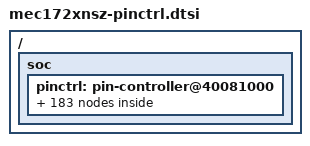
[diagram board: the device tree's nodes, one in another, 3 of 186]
/*
 * Copyright (c) 2021 Microchip Technology Inc.
 *
 * SPDX-License-Identifier: Apache-2.0
 */

#include <dt-bindings/pinctrl/mchp-xec-pinctrl.h>

/ {
	soc {
		pinctrl: pin-controller@40081000 {

			/* ADC */
			pinctrl_adc0_in0: adc0_in0 {
				pinmux = < MCHP_XEC_PINMUX(0200, AF1) >;
			};

			pinctrl_adc0_in1: adc0_in1 {
				pinmux = < MCHP_XEC_PINMUX(0201, AF1) >;
			};

			pinctrl_adc0_in2: adc0_in2 {
				pinmux = < MCHP_XEC_PINMUX(0202, AF1) >;
			};

			pinctrl_adc0_in3: adc0_in3 {
				pinmux = < MCHP_XEC_PINMUX(0203, AF1) >;
			};

			pinctrl_adc0_in4: adc0_in4 {
				pinmux = < MCHP_XEC_PINMUX(0204, AF1) >;
			};

			pinctrl_adc0_in5: adc0_in5 {
				pinmux = < MCHP_XEC_PINMUX(0205, AF1) >;
			};

			pinctrl_adc0_in6: adc0_in6 {
				pinmux = < MCHP_XEC_PINMUX(0206, AF1) >;
			};

			pinctrl_adc0_in7: adc0_in7 {
				pinmux = < MCHP_XEC_PINMUX(0207, AF1) >;
			};

			pinctrl_adc0_vref2: adc0_vref2 {
				pinmux = < MCHP_XEC_PINMUX(067, AF1) >;
			};

			/* BBLED */
			pinctrl_bbled0: bbled0 {
				pinmux = < MCHP_XEC_PINMUX(0156, AF1) >;
			};

			pinctrl_bbled1: bbled1 {
				pinmux = < MCHP_XEC_PINMUX(0157, AF1) >;
			};

			pinctrl_bbled1: bbled1 {
				pinmux = < MCHP_XEC_PINMUX(0153, AF1) >;
			};

			/* eSPI */
			pinctrl_espi_alert: espi_alert {
				pinmux = < MCHP_XEC_PINMUX(063, AF1) >;
				bias-pull-up;
				drive-open-drain;
			};

			pinctrl_espi_clk: espi_clk {
				pinmux = < MCHP_XEC_PINMUX(065, AF1) >;
				slew-rate = "high-speed";
			};

			pinctrl_espi_cs: espi_cs {
				pinmux = < MCHP_XEC_PINMUX(066, AF1) >;
				bias-pull-up;
				drive-open-drain;
			};

			pinctrl_espi_io0: espi_io0 {
				pinmux = < MCHP_XEC_PINMUX(070, AF1) >;
				slew-rate = "high-speed";
			};

			pinctrl_espi_io1: espi_io1 {
				pinmux = < MCHP_XEC_PINMUX(071, AF1) >;
				slew-rate = "high-speed";
			};

			pinctrl_espi_io2: espi_io2 {
				pinmux = < MCHP_XEC_PINMUX(072, AF1) >;
				slew-rate = "high-speed";
			};

			pinctrl_espi_io3: espi_io3 {
				pinmux = < MCHP_XEC_PINMUX(073, AF1) >;
				slew-rate = "high-speed";
			};

			pinctrl_espi_reset: espi_reset {
				pinmux = < MCHP_XEC_PINMUX(061, AF1) >;
				bias-pull-up;
				drive-open-drain;
			};

			/* GPIO Pass Through */
			pinctrl_gptp_in0: gptp_in0 {
				pinmux = < MCHP_XEC_PINMUX(0224, AF1) >;
			};

			pinctrl_gptp_out0: gptp_out0 {
				pinmux = < MCHP_XEC_PINMUX(032, AF2) >;
			};

			pinctrl_gptp_in1: gptp_in1 {
				pinmux = < MCHP_XEC_PINMUX(016, AF1) >;
			};

			pinctrl_gptp_out1: gptp_out1 {
				pinmux = < MCHP_XEC_PINMUX(031, AF2) >;
			};

			pinctrl_gptp_in2: gptp_in2 {
				pinmux = < MCHP_XEC_PINMUX(014, AF3) >;
			};

			pinctrl_gptp_out2: gptp_out2 {
				pinmux = < MCHP_XEC_PINMUX(040, AF1) >;
			};

			pinctrl_gptp_in3: gptp_in3 {
				pinmux = < MCHP_XEC_PINMUX(0221, AF2) >;
			};

			pinctrl_gptp_out3: gptp_out3 {
				pinmux = < MCHP_XEC_PINMUX(0152, AF3) >;
			};

			pinctrl_gptp_in5: gptp_in5 {
				pinmux = < MCHP_XEC_PINMUX(017, AF3) >;
			};

			pinctrl_gptp_out5: gptp_out5 {
				pinmux = < MCHP_XEC_PINMUX(0125, AF3) >;
			};

			pinctrl_gptp_in6: gptp_in6 {
				pinmux = < MCHP_XEC_PINMUX(024, AF2) >;
			};

			pinctrl_gptp_out6: gptp_out6 {
				pinmux = < MCHP_XEC_PINMUX(0124, AF4) >;
			};

			/* I2C port 0 */
			pinctrl_i2c_scl0: i2c_scl0 {
				pinmux = < MCHP_XEC_PINMUX(004, AF1) >;
				drive-open-drain;
				output-high;
			};

			pinctrl_i2c_sda0: i2c_sda0 {
				pinmux = < MCHP_XEC_PINMUX(003, AF1) >;
				drive-open-drain;
				output-high;
			};

			/* I2C port 1 */
			pinctrl_i2c_scl1: i2c_scl1 {
				pinmux = < MCHP_XEC_PINMUX(0131, AF1) >;
				drive-open-drain;
				output-high;
			};

			pinctrl_i2c_scl1_alt: i2c_scl1_alt {
				pinmux = < MCHP_XEC_PINMUX(073, AF2) >;
				drive-open-drain;
				output-high;
			};

			pinctrl_i2c_sda1: i2c_sda1 {
				pinmux = < MCHP_XEC_PINMUX(0130, AF1) >;
				drive-open-drain;
				output-high;
			};

			pinctrl_i2c_sda1_alt: i2c_sda1_alt {
				pinmux = < MCHP_XEC_PINMUX(072, AF2) >;
				drive-open-drain;
				output-high;
			};

			/* I2C port 2 */
			pinctrl_i2c_scl2: i2c_scl2 {
				pinmux = < MCHP_XEC_PINMUX(0155, AF1) >;
				drive-open-drain;
				output-high;
			};

			pinctrl_i2c_sda2: i2c_sda2 {
				pinmux = < MCHP_XEC_PINMUX(0154, AF1) >;
				drive-open-drain;
				output-high;
			};

			/* I2C port 3 */
			pinctrl_i2c_scl3: i2c_scl3 {
				pinmux = < MCHP_XEC_PINMUX(010, AF1) >;
				drive-open-drain;
				output-high;
			};

			pinctrl_i2c_sda3: i2c_sda3 {
				pinmux = < MCHP_XEC_PINMUX(007, AF1) >;
				drive-open-drain;
				output-high;
			};

			/* I2C port 4 */
			pinctrl_i2c_scl4: i2c_scl4 {
				pinmux = < MCHP_XEC_PINMUX(0144, AF1) >;
				drive-open-drain;
				output-high;
			};

			pinctrl_i2c_sda4: i2c_sda4 {
				pinmux = < MCHP_XEC_PINMUX(0143, AF1) >;
				drive-open-drain;
				output-high;
			};

			/* I2C port 5 */
			pinctrl_i2c_scl5: i2c_scl5 {
				pinmux = < MCHP_XEC_PINMUX(0142, AF1) >;
				drive-open-drain;
				output-high;
			};

			pinctrl_i2c_sda5: i2c_sda5 {
				pinmux = < MCHP_XEC_PINMUX(0141, AF1) >;
				drive-open-drain;
				output-high;
			};

			/* I2C port 6 */
			pinctrl_i2c_scl6: i2c_scl6 {
				pinmux = < MCHP_XEC_PINMUX(0140, AF1) >;
				drive-open-drain;
				output-high;
			};

			pinctrl_i2c_sda6: i2c_sda6 {
				pinmux = < MCHP_XEC_PINMUX(0132, AF1) >;
				drive-open-drain;
				output-high;
			};

			/* I2C port 7 */
			pinctrl_i2c_scl7: i2c_scl7 {
				pinmux = < MCHP_XEC_PINMUX(013, AF1) >;
				drive-open-drain;
				output-high;
			};

			pinctrl_i2c_scl7_alt: i2c_scl7_alt {
				pinmux = < MCHP_XEC_PINMUX(024, AF3) >;
				drive-open-drain;
				output-high;
			};

			pinctrl_i2c_sda7: i2c_sda7 {
				pinmux = < MCHP_XEC_PINMUX(012, AF1) >;
				drive-open-drain;
				output-high;
			};

			pinctrl_i2c_sda7_alt: i2c_sda7_alt {
				pinmux = < MCHP_XEC_PINMUX(0152, AF3) >;
				drive-open-drain;
				output-high;
			};

			/* I2C port 9 */
			pinctrl_i2c_scl9: i2c_scl9 {
				pinmux = < MCHP_XEC_PINMUX(0146, AF1) >;
				drive-open-drain;
				output-high;
			};

			pinctrl_i2c_sda9: i2c_sda9 {
				pinmux = < MCHP_XEC_PINMUX(0145, AF1) >;
				drive-open-drain;
				output-high;
			};

			/* I2C port 10 */
			pinctrl_i2c_scl10: i2c_scl10 {
				pinmux = < MCHP_XEC_PINMUX(0107, AF3) >;
				drive-open-drain;
				output-high;
			};

			pinctrl_i2c_sda10: i2c_sda10 {
				pinmux = < MCHP_XEC_PINMUX(030, AF2) >;
				drive-open-drain;
				output-high;
			};

			/* I2C port 11 */
			pinctrl_i2c_scl11: i2c_scl11 {
				pinmux = < MCHP_XEC_PINMUX(062, AF2) >;
				drive-open-drain;
				output-high;
			};

			pinctrl_i2c_sda11: i2c_sda11 {
				pinmux = < MCHP_XEC_PINMUX(000, AF3) >;
				drive-open-drain;
				output-high;
			};

			/* I2C port 12 */
			pinctrl_i2c_scl12: i2c_scl12 {
				pinmux = < MCHP_XEC_PINMUX(027, AF3) >;
				drive-open-drain;
				output-high;
			};

			pinctrl_i2c_sda12: i2c_sda12 {
				pinmux = < MCHP_XEC_PINMUX(026, AF3) >;
				drive-open-drain;
				output-high;
			};

			/* I2C port 13 */
			pinctrl_i2c_scl13: i2c_scl13 {
				pinmux = < MCHP_XEC_PINMUX(065, AF2) >;
				drive-open-drain;
				output-high;
			};

			pinctrl_i2c_sda13: i2c_sda13 {
				pinmux = < MCHP_XEC_PINMUX(066, AF2) >;
				drive-open-drain;
				output-high;
			};

			/* I2C port 14 */
			pinctrl_i2c_scl14: i2c_scl14 {
				pinmux = < MCHP_XEC_PINMUX(071, AF2) >;
				drive-open-drain;
				output-high;
			};

			pinctrl_i2c_sda14: i2c_sda14 {
				pinmux = < MCHP_XEC_PINMUX(070, AF2) >;
				drive-open-drain;
				output-high;
			};

			/* I2C port 15 */
			pinctrl_i2c_scl15: i2c_scl15 {
				pinmux = < MCHP_XEC_PINMUX(0150, AF1) >;
				drive-open-drain;
				output-high;
			};

			pinctrl_sda15: i2c_sda15 {
				pinmux = < MCHP_XEC_PINMUX(0147, AF1) >;
				drive-open-drain;
				output-high;
			};

			/* KEYSCAN */
			pinctrl_ksi0: ksi0 {
				pinmux = < MCHP_XEC_PINMUX(017, AF1) >;
				bias-pull-up;
				drive-open-drain;
			};

			pinctrl_ksi1: ksi1 {
				pinmux = < MCHP_XEC_PINMUX(020, AF1) >;
				bias-pull-up;
				drive-open-drain;
			};

			pinctrl_ksi2: ksi2 {
				pinmux = < MCHP_XEC_PINMUX(021, AF1) >;
				bias-pull-up;
				drive-open-drain;
			};

			pinctrl_ksi3: ksi3 {
				pinmux = < MCHP_XEC_PINMUX(026, AF1) >;
				bias-pull-up;
				drive-open-drain;
			};

			pinctrl_ksi4: ksi4 {
				pinmux = < MCHP_XEC_PINMUX(027, AF1) >;
				bias-pull-up;
				drive-open-drain;
			};

			pinctrl_ksi5: ksi5 {
				pinmux = < MCHP_XEC_PINMUX(030, AF1) >;
				bias-pull-up;
				drive-open-drain;
			};

			pinctrl_ksi6: ksi6 {
				pinmux = < MCHP_XEC_PINMUX(031, AF1) >;
				bias-pull-up;
				drive-open-drain;
			};

			pinctrl_ksi7: ksi7 {
				pinmux = < MCHP_XEC_PINMUX(032, AF1) >;
				bias-pull-up;
				drive-open-drain;
			};

			pinctrl_kso0: kso0 {
				pinmux = < MCHP_XEC_PINMUX(040, AF2) >;
				bias-pull-up;
				drive-open-drain;
			};

			pinctrl_kso1: kso1 {
				pinmux = < MCHP_XEC_PINMUX(045, AF1) >;
				bias-pull-up;
				drive-open-drain;
			};

			pinctrl_kso2: kso2 {
				pinmux = < MCHP_XEC_PINMUX(046, AF1) >;
				bias-pull-up;
				drive-open-drain;
			};

			pinctrl_kso3: kso3 {
				pinmux = < MCHP_XEC_PINMUX(047, AF1) >;
				bias-pull-up;
				drive-open-drain;
			};

			pinctrl_kso4: kso4 {
				pinmux = < MCHP_XEC_PINMUX(0107, AF2) >;
				bias-pull-up;
				drive-open-drain;
			};

			pinctrl_kso5: kso5 {
				pinmux = < MCHP_XEC_PINMUX(0112, AF1) >;
				bias-pull-up;
				drive-open-drain;
			};

			pinctrl_kso6: kso6 {
				pinmux = < MCHP_XEC_PINMUX(0113, AF1) >;
				bias-pull-up;
				drive-open-drain;
			};

			pinctrl_kso7: kso7 {
				pinmux = < MCHP_XEC_PINMUX(0120, AF1) >;
				bias-pull-up;
				drive-open-drain;
			};

			pinctrl_kso8: kso8 {
				pinmux = < MCHP_XEC_PINMUX(0121, AF2) >;
				bias-pull-up;
				drive-open-drain;
			};

			pinctrl_kso9: kso9 {
				pinmux = < MCHP_XEC_PINMUX(0122, AF2) >;
				bias-pull-up;
				drive-open-drain;
			};

			pinctrl_kso10: kso10 {
				pinmux = < MCHP_XEC_PINMUX(0123, AF2) >;
				bias-pull-up;
				drive-open-drain;
			};

			pinctrl_kso11: kso11 {
				pinmux = < MCHP_XEC_PINMUX(0124, AF2) >;
				bias-pull-up;
				drive-open-drain;
			};

			pinctrl_kso12: kso12 {
				pinmux = < MCHP_XEC_PINMUX(0125, AF2) >;
				bias-pull-up;
				drive-open-drain;
			};

			pinctrl_kso13: kso13 {
				pinmux = < MCHP_XEC_PINMUX(0126, AF2) >;
				bias-pull-up;
				drive-open-drain;
			};

			pinctrl_kso14: kso14 {
				pinmux = < MCHP_XEC_PINMUX(0152, AF1) >;
				bias-pull-up;
				drive-open-drain;
			};

			pinctrl_kso15: kso15 {
				pinmux = < MCHP_XEC_PINMUX(0151, AF2) >;
				bias-pull-up;
				drive-open-drain;
			};

			pinctrl_kso16: kso16 {
				pinmux = < MCHP_XEC_PINMUX(0132, AF2) >;
				bias-pull-up;
				drive-open-drain;
			};

			pinctrl_kso17: kso17 {
				pinmux = < MCHP_XEC_PINMUX(0140, AF3) >;
				bias-pull-up;
				drive-open-drain;
			};

			/* Quad SPI Shared Port. Two chip selects */
			pinctrl_qshd_cs0: qshd_cs0 {
				pinmux = < MCHP_XEC_PINMUX(055, AF2) >;
				drive-open-drain;
				output-high;
			};

			pinctrl_qshd_cs1: qshd_cs1 {
				pinmux = < MCHP_XEC_PINMUX(002, AF2) >;
				drive-open-drain;
				output-high;
			};

			pinctrl_qshd_clk: qshd_clk {
				pinmux = < MCHP_XEC_PINMUX(056, AF2) >;
			};

			pinctrl_qshd_io0: qshd_io0 {
				pinmux = < MCHP_XEC_PINMUX(0223, AF1) >;
			};

			pinctrl_qshd_io1: qshd_io1 {
				pinmux = < MCHP_XEC_PINMUX(0224, AF2) >;
			};

			pinctrl_qshd_io2: qshd_io2 {
				pinmux = < MCHP_XEC_PINMUX(0227, AF1) >;
			};

			pinctrl_qshd_io3: qshd_io3 {
				pinmux = < MCHP_XEC_PINMUX(016, AF2) >;
			};

			/* Quad SPI Private Port. One chip select */
			pinctrl_qpvt_cs0: qpvt_cs0 {
				pinmux = < MCHP_XEC_PINMUX(0124, AF1) >;
				drive-open-drain;
				output-high;
			};

			pinctrl_qpvt_io0: qpvt_io0 {
				pinmux = < MCHP_XEC_PINMUX(0121, AF1) >;
			};

			pinctrl_qpvt_io1: qpvt_io1 {
				pinmux = < MCHP_XEC_PINMUX(0122, AF1) >;
			};

			pinctrl_qpvt_io2: qpvt_io2 {
				pinmux = < MCHP_XEC_PINMUX(0123, AF1) >;
			};

			pinctrl_qpvt_io3: qpvt_io3 {
				pinmux = < MCHP_XEC_PINMUX(0126, AF1) >;
			};

			pinctrl_qpvt_clk: qpvt_clk {
				pinmux = < MCHP_XEC_PINMUX(0125, AF1) >;
			};

			/* Quad SPI Internal Port. No quad support.
			 * One chip select. nHOLD is tied to VTR1.
			 * Requires internal pull-up enabled.
			 * No need for open drain since there is only one device
			 * attached (flash).
			 */
			pinctrl_qint_cs0: qint_cs0 {
				pinmux = < MCHP_XEC_PINMUX(0116, AF1) >;
				bias-pull-up;
				output-high;
			};

			pinctrl_qint_clk: qint_clk {
				pinmux =  < MCHP_XEC_PINMUX(0117, AF1) >;
			};

			pinctrl_qint_io0: qint_io0 {
				pinmux = < MCHP_XEC_PINMUX(074, AF1) >;
			};

			pinctrl_qint_io1: qint_io1 {
				pinmux = < MCHP_XEC_PINMUX(075, AF1) >;
			};

			pinctrl_qint_wpn: qint_wpn {
				pinmux = < MCHP_XEC_PINMUX(076, 0) >;
				bias-pull-up;
				output-high;
			};

			/* PECI */
			pinctrl_peci_dat: peci_dat {
				pinmux = < MCHP_XEC_PINMUX(042, AF1) >;
			};

			pinctrl_vref_vtt: vref_vtt {
				pinmux = < MCHP_XEC_PINMUX(044, AF1) >;
			};

			/* PROCHOT */
			pinctrl_prochot_in: prochot_in {
				pinmux = < MCHP_XEC_PINMUX(0222, AF2) >;
				drive-open-drain;
			};

			/* PS2 */
			pinctrl_ps2_clk0a: ps2_clk0a {
				pinmux = < MCHP_XEC_PINMUX(0114, AF1) >;
			};

			pinctrl_ps2_dat0a: ps2_dat0a {
				pinmux = < MCHP_XEC_PINMUX(0115, AF1) >;
			};

			pinctrl_ps2_clk0b: ps2_clk0b {
				pinmux = < MCHP_XEC_PINMUX(007, AF2) >;
			};

			pinctrl_ps2_dat0b: ps2_dat0b {
				pinmux = < MCHP_XEC_PINMUX(010, AF2) >;
			};

			/* PWM */
			pinctrl_pwm0: pwm0 {
				pinmux = < MCHP_XEC_PINMUX(053, AF1) >;
			};

			pinctrl_pwm0_alt: pwm0_out_alt {
				pinmux = < MCHP_XEC_PINMUX(0241, AF4) >;
			};

			pinctrl_pwm1: pwm1 {
				pinmux = < MCHP_XEC_PINMUX(054, AF1) >;
			};

			pinctrl_pwm2: pwm2 {
				pinmux = < MCHP_XEC_PINMUX(055, AF1) >;
			};

			pinctrl_pwm2_alt: pwm2_alt {
				pinmux = < MCHP_XEC_PINMUX(045, AF2) >;
			};

			pinctrl_pwm3: pwm3 {
				pinmux = < MCHP_XEC_PINMUX(056, AF1) >;
			};

			pinctrl_pwm3_alt: pwm3_alt {
				pinmux = < MCHP_XEC_PINMUX(047, AF2) >;
			};

			pinctrl_pwm4: pwm4 {
				pinmux = < MCHP_XEC_PINMUX(011, AF2) >;
			};

			pinctrl_pwm5: pwm5 {
				pinmux = < MCHP_XEC_PINMUX(002, AF1) >;
			};

			pinctrl_pwm6: pwm6 {
				pinmux = < MCHP_XEC_PINMUX(014, AF1) >;
			};

			pinctrl_pwm6_alt: pwm6_alt {
				pinmux = < MCHP_XEC_PINMUX(063, AF2) >;
			};

			pinctrl_pwm7: pwm7 {
				pinmux = < MCHP_XEC_PINMUX(015, AF1) >;
			};

			pinctrl_pwm8: pwm8 {
				pinmux = < MCHP_XEC_PINMUX(035, AF1) >;
			};

			pinctrl_pwm8_alt: pwm8_alt {
				pinmux = < MCHP_XEC_PINMUX(0175, AF3) >;
			};

			/* RC_ID */
			pinctrl_rcid0: rcid0 {
				pinmux = < MCHP_XEC_PINMUX(033, AF2) >;
			};

			pinctrl_rcid1: rcid1 {
				pinmux = < MCHP_XEC_PINMUX(034, AF2) >;
			};

			pinctrl_rcid2: rcid2 {
				pinmux = < MCHP_XEC_PINMUX(036, AF2) >;
			};

			/* RPM Fan  */
			pinctrl_gpwm0: gpwm0 {
				pinmux = < MCHP_XEC_PINMUX(053, AF3) >;
			};

			pinctrl_gtach0: gtach0 {
				pinmux = < MCHP_XEC_PINMUX(050, AF2) >;
			};

			pinctrl_gpwm1: gpwm1 {
				pinmux = < MCHP_XEC_PINMUX(054, AF3) >;
			};

			pinctrl_gtach1: gtach1 {
				pinmux = < MCHP_XEC_PINMUX(051, AF2) >;
			};

			/* SB-TSI */
			pinctrl_sbtsi_dat: sbtsi_dat {
				pinmux = < MCHP_XEC_PINMUX(042, AF2) >;
			};

			pinctrl_sbtsi_clk: sbtsi_clk {
				pinmux = < MCHP_XEC_PINMUX(043, AF1) >;
			};

			/* General Purpose SPI Controller 0 */
			pinctrl_spi0_miso: spi0_miso {
				pinmux = < MCHP_XEC_PINMUX(036, AF3) >;
			};

			pinctrl_spi0_mosi: spi0_mosi {
				pinmux = < MCHP_XEC_PINMUX(004, AF4) >;
			};

			pinctrl_spi0_clk: spi0_clk {
				pinmux = < MCHP_XEC_PINMUX(034, AF4) >;
			};

			pinctrl_spi0_cs0: spi0_cs0 {
				pinmux = < MCHP_XEC_PINMUX(003, AF4) >;
			};

			pinctrl_spi0_cs1: spi0_cs1 {
				pinmux = < MCHP_XEC_PINMUX(060, AF4) >;
			};

			/* General Purpose SPI Controller 1 */
			pinctrl_spi1_miso: spi1_miso {
				pinmux = < MCHP_XEC_PINMUX(0143, AF3) >;
			};

			pinctrl_spi1_mosi: spi1_mosi {
				pinmux = < MCHP_XEC_PINMUX(0142, AF3) >;
			};

			pinctrl_spi1_clk: spi1_clk {
				pinmux = < MCHP_XEC_PINMUX(0141, AF3) >;
			};

			pinctrl_spi1_cs: spi1_cs {
				pinmux = < MCHP_XEC_PINMUX(0144, AF3) >;
			};

			/* TACH */
			pinctrl_tach0: tach0 {
				pinmux = < MCHP_XEC_PINMUX(050, AF1) >;
			};

			pinctrl_tach1: tach1 {
				pinmux = < MCHP_XEC_PINMUX(051, AF1) >;
			};

			pinctrl_tach2: tach2 {
				pinmux = < MCHP_XEC_PINMUX(052, AF1) >;
			};

			/* UART0 */
			pinctrl_uart0_rx: uart0_rx {
				pinmux = < MCHP_XEC_PINMUX(0105, AF1) >;
			};

			pinctrl_uart0_tx: uart0_tx {
				pinmux = < MCHP_XEC_PINMUX(0104, AF1) >;
				bias-pull-up;
			};

			pinctrl_uart0_cts: uart0_cts {
				pinmux = < MCHP_XEC_PINMUX(0143, AF2) >;
				bias-pull-up;
				drive-open-drain;
			};

			pinctrl_uart0_cts_alt: uart0_cts_alt {
				pinmux = < MCHP_XEC_PINMUX(0127, AF3) >;
				bias-pull-up;
				drive-open-drain;
			};

			pinctrl_uart0_dcd: uart0_dcd {
				pinmux = < MCHP_XEC_PINMUX(017, AF2) >;
				bias-pull-up;
				drive-open-drain;
			};

			pinctrl_uart0_dcd_alt: uart0_dcd_alt {
				pinmux = < MCHP_XEC_PINMUX(0141, AF4) >;
				bias-pull-up;
				drive-open-drain;
			};

			pinctrl_uart0_dtr: uart0_dtr {
				pinmux = < MCHP_XEC_PINMUX(026, AF2) >;
				bias-pull-up;
				drive-open-drain;
			};

			pinctrl_uart0_dtr_alt: uart0_dtr_alt {
				pinmux = < MCHP_XEC_PINMUX(0143, AF4) >;
				bias-pull-up;
				drive-open-drain;
			};

			pinctrl_uart0_ri: uart0_ri {
				pinmux = < MCHP_XEC_PINMUX(032, AF3) >;
				bias-pull-up;
				drive-open-drain;
			};

			pinctrl_uart0_ri_alt: uart0_ri_alt {
				pinmux = < MCHP_XEC_PINMUX(0144, AF4) >;
				bias-pull-up;
				drive-open-drain;
			};

			pinctrl_uart0_rts: uart0_rts {
				pinmux = < MCHP_XEC_PINMUX(0144, AF2) >;
				bias-pull-up;
				drive-open-drain;
			};

			/* UART1 */
			pinctrl_uart1_rx: uart1_rx {
				pinmux = < MCHP_XEC_PINMUX(0171, AF1) >;
			};

			pinctrl_uart1_tx: uart1_tx {
				pinmux = < MCHP_XEC_PINMUX(0170, AF1) >;
				bias-pull-up;
			};

			pinctrl_uart1_rx_alt: uart1_rx_alt {
				pinmux = < MCHP_XEC_PINMUX(0255, AF1) >;
			};

			pinctrl_uart1_cts: uart1_cts {
				pinmux = < MCHP_XEC_PINMUX(040, AF3) >;
				bias-pull-up;
				drive-open-drain;
			};

			pinctrl_uart1_dcd: uart1_dcd {
				pinmux = < MCHP_XEC_PINMUX(060, AF3) >;
				bias-pull-up;
				drive-open-drain;
			};

			pinctrl_uart1_dtr: uart1_dtr {
				pinmux = < MCHP_XEC_PINMUX(0120, AF2) >;
				bias-pull-up;
				drive-open-drain;
			};

			pinctrl_uart1_ri: uart1_ri {
				pinmux = < MCHP_XEC_PINMUX(025, AF3) >;
				bias-pull-up;
				drive-open-drain;
			};

			pinctrl_uart1_rts: uart1_rts {
				pinmux = < MCHP_XEC_PINMUX(0127, AF2) >;
				bias-pull-up;
				drive-open-drain;
			};

			/* VCI */
			pinctrl_vci_in1: vci_in1 {
				pinmux = < MCHP_XEC_PINMUX(0162, AF1) >;
			};

			pinctrl_vci_in2: vci_in2 {
				pinmux = < MCHP_XEC_PINMUX(0161, AF1) >;
			};

			pinctrl_vci_in3: vci_in3 {
				pinmux = < MCHP_XEC_PINMUX(000, AF1) >;
			};

			/* Week timer BGPO pins */
			pinctrl_bgpo1: bgpo1 {
				pinmux = < MCHP_XEC_PINMUX(0101, AF1) >;
			};

			pinctrl_bgpo2: bgpo2 {
				pinmux = < MCHP_XEC_PINMUX(0102, AF1) >;
			};

			/* Analog Voltage Comparator */
			pinctrl_cmp_vin0: cmp_vin0 {
				pinmux = < MCHP_XEC_PINMUX(057, AF2) >;
			};

			pinctrl_cmp_vout0: cmp_vout0 {
				pinmux = < MCHP_XEC_PINMUX(0241, AF3) >;
			};

			pinctrl_cmp_vref0: cmp_vref0 {
				pinmux = < MCHP_XEC_PINMUX(0226, AF3) >;
			};

			pinctrl_cmp_vin1: cmp_vin1 {
				pinmux = < MCHP_XEC_PINMUX(0221, AF3) >;
			};

			pinctrl_cmp_vout1: cmp_vout1 {
				pinmux = < MCHP_XEC_PINMUX(0175, AF1) >;
			};

			pinctrl_cmp_vref1: cmp_vref1 {
				pinmux = < MCHP_XEC_PINMUX(0106, AF2) >;
			};

			/* TFDP */
			pinctrl_tfdp_clk: tfdp_clk {
				pinmux = < MCHP_XEC_PINMUX(0170, AF2) >;
			};

			pinctrl_tfdp_dat: tfdp_dat {
				pinmux = < MCHP_XEC_PINMUX(0171, AF2) >;
			};
		};
	};
};
